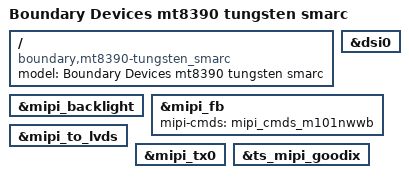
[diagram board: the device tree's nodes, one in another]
// SPDX-License-Identifier: (GPL-2.0 OR MIT)
/*
 * Copyright 2023 Boundary Devices
 */
/dts-v1/;
#include "mt8390-tungsten_smarc-som.dtsi"
#include "../bd-universal-smarc-carrier.dtsi"

/ {
	model = "Boundary Devices mt8390 tungsten smarc";
	compatible = "boundary,mt8390-tungsten_smarc", "mediatek,mt8188";
};

#if !defined(UBOOT) && 1
&dsi0 {
	status = "okay";
};

&mipi_backlight {
	status = "okay";
};

&mipi_fb {
	mipi-cmds = <&mipi_cmds_m101nwwb>;
	status = "okay";
};

&mipi_to_lvds {
	status = "okay";
};

&mipi_tx0 {
	status = "okay";
};

&ts_mipi_goodix {
	status = "okay";
};
#endif


#if !defined(UBOOT) && 0
&dsi1 {
	status = "okay";
};

&mipi1_backlight {
	status = "okay";
};

&mipi1_fb {
	mipi-cmds = <&mipi_cmds_m101nwwb>;
	status = "okay";
};

&mipi1_to_lvds {
	status = "okay";
};

&mipi_tx1 {
	status = "okay";
};

&ts_mipi1_goodix {
	status = "okay";
};
#endif
